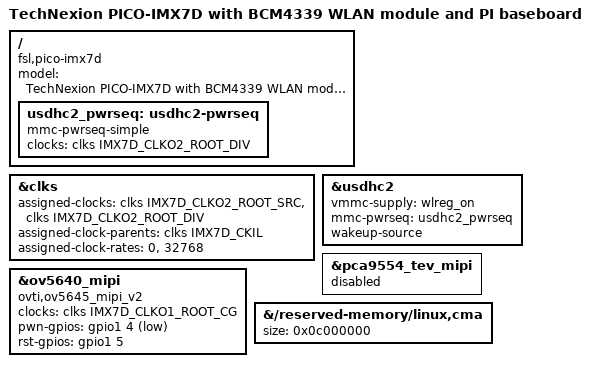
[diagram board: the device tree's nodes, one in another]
/*
 * Keep the Ubuntu image's QCA display wiring, add the Broadcom AP6335 SDIO
 * clock/power sequence, and restore the CAM-OV5645 wiring from TechNexion's
 * PICO-PI i.MX7 Yocto/Android-era device tree.
 */
/dts-v1/;

#include "imx7d.dtsi"
#include "imx7d-pico-qca.dtsi"
#include "baseboard_pico_pi.dtsi"

/ {
	model = "TechNexion PICO-IMX7D with BCM4339 WLAN module and PI baseboard";
	compatible = "fsl,pico-imx7d", "fsl,imx7d";

	usdhc2_pwrseq: usdhc2-pwrseq {
		compatible = "mmc-pwrseq-simple";
		clocks = <&clks IMX7D_CLKO2_ROOT_DIV>;
		clock-names = "ext_clock";
	};
};

&clks {
	assigned-clocks = <&clks IMX7D_CLKO2_ROOT_SRC>,
			  <&clks IMX7D_CLKO2_ROOT_DIV>;
	assigned-clock-parents = <&clks IMX7D_CKIL>;
	assigned-clock-rates = <0>, <32768>;
};

&usdhc2 {
	vmmc-supply = <&wlreg_on>;
	mmc-pwrseq = <&usdhc2_pwrseq>;
	wakeup-source;
};

/*
 * The Ubuntu DTB describes a TEVI OV5640 plus PCA9554 at I2C address 0x24.
 * The PICO-PI kit's CAM-OV5645 instead uses direct GPIO1_4 power-down,
 * GPIO1_5 reset, and CLKO1.  Retain the existing endpoint label so the
 * receiver graph inherited from imx7d-pico-qca.dtsi stays connected.
 */
&ov5640_mipi {
	compatible = "ovti,ov5645_mipi_v2";
	clocks = <&clks IMX7D_CLKO1_ROOT_CG>;
	pwn-gpios = <&gpio1 4 1>;
	rst-gpios = <&gpio1 5 0>;
};

&pca9554_tev_mipi {
	status = "disabled";
};

// Preserve the validated 192 MiB CMA reservation on the inspected boards.
&{/reserved-memory/linux,cma} {
	size = <0x0c000000>;
};
